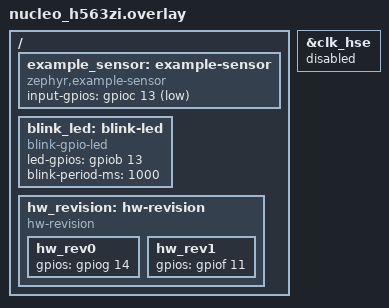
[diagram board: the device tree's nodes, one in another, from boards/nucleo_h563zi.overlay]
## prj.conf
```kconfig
# Copyright (c) 2021 Nordic Semiconductor ASA
# SPDX-License-Identifier: Apache-2.0
#
# This file contains selected Kconfig options for the application.

CONFIG_SENSOR=y
CONFIG_BLINK=y
CONFIG_HW_REVISION=y
```

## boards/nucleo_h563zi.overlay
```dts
/*
 * Copyright (c) 2024 Thorsten Spätling <thorsten.spaetling@vierling.de>
 * SPDX-License-Identifier: Apache-2.0
 */

/* This devicetree overlay file will be automatically picked by the Zephyr
 * build system when building the sample for the nucleo_h563zi board. It shows
 * how the example-application can be built on sample boards already provided
 * by Zephyr.
 */

/ {
	example_sensor: example-sensor {
		compatible = "zephyr,example-sensor";
		input-gpios = <&gpioc 13 (GPIO_PULL_UP | GPIO_ACTIVE_LOW)>;
	};

	blink_led: blink-led {
		compatible = "blink-gpio-led";
		led-gpios = <&gpiob 13 GPIO_ACTIVE_HIGH>;
		blink-period-ms = <1000>;
	};

	hw_revision: hw-revision {
		compatible = "hw-revision";
		hw_rev0 {
			gpios = <&gpiog 14 (GPIO_PULL_UP | GPIO_ACTIVE_HIGH)>;
		};
		hw_rev1 {
			gpios = <&gpiof 11 (GPIO_PULL_UP | GPIO_ACTIVE_HIGH)>;
		};
	};
};

&clk_hse {
	status = "disabled";//without deadlock
};
```

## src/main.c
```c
/*
 * Copyright (c) 2021 Nordic Semiconductor ASA
 * SPDX-License-Identifier: Apache-2.0
 */

#include <zephyr/kernel.h>
#include <zephyr/drivers/sensor.h>
#include <zephyr/logging/log.h>

#include <app/drivers/blink.h>

#include <app_version.h>

LOG_MODULE_REGISTER(main, CONFIG_APP_LOG_LEVEL);

#define BLINK_PERIOD_MS_STEP 100U
#define BLINK_PERIOD_MS_MAX  1000U

int main(void)
{
	int ret;
	unsigned int period_ms = BLINK_PERIOD_MS_MAX;
	const struct device *sensor, *blink, *hw_rev;
	struct sensor_value last_val = { 0 }, val;

	printk("Zephyr Example Application %s\n", APP_VERSION_STRING);

	hw_rev = DEVICE_DT_GET(DT_NODELABEL(hw_revision));
	if (!device_is_ready(hw_rev)) {
		LOG_ERR("hardware revision not ready");
		return 0;
	}

	sensor = DEVICE_DT_GET(DT_NODELABEL(example_sensor));
	if (!device_is_ready(sensor)) {
		LOG_ERR("Sensor not ready");
		return 0;
	}

	blink = DEVICE_DT_GET(DT_NODELABEL(blink_led));
	if (!device_is_ready(blink)) {
		LOG_ERR("Blink LED not ready");
		return 0;
	}


	ret = blink_off(blink);
	if (ret < 0) {
		LOG_ERR("Could not turn off LED (%d)", ret);
		return 0;
	}

	printk("Use the sensor to change LED blinking period\n");

	while (1) {
		ret = sensor_sample_fetch(sensor);
		if (ret < 0) {
			LOG_ERR("Could not fetch sample (%d)", ret);
			return 0;
		}

		ret = sensor_channel_get(sensor, SENSOR_CHAN_PROX, &val);
		if (ret < 0) {
			LOG_ERR("Could not get sample (%d)", ret);
			return 0;
		}

		if ((last_val.val1 == 0) && (val.val1 == 1)) {
			if (period_ms == 0U) {
				period_ms = BLINK_PERIOD_MS_MAX;
			} else {
				period_ms -= BLINK_PERIOD_MS_STEP;
			}

			printk("Proximity detected, setting LED period to %u ms\n",
			       period_ms);
			blink_set_period_ms(blink, period_ms);
		}

		last_val = val;

		k_sleep(K_MSEC(100));
	}

	return 0;
}
```
